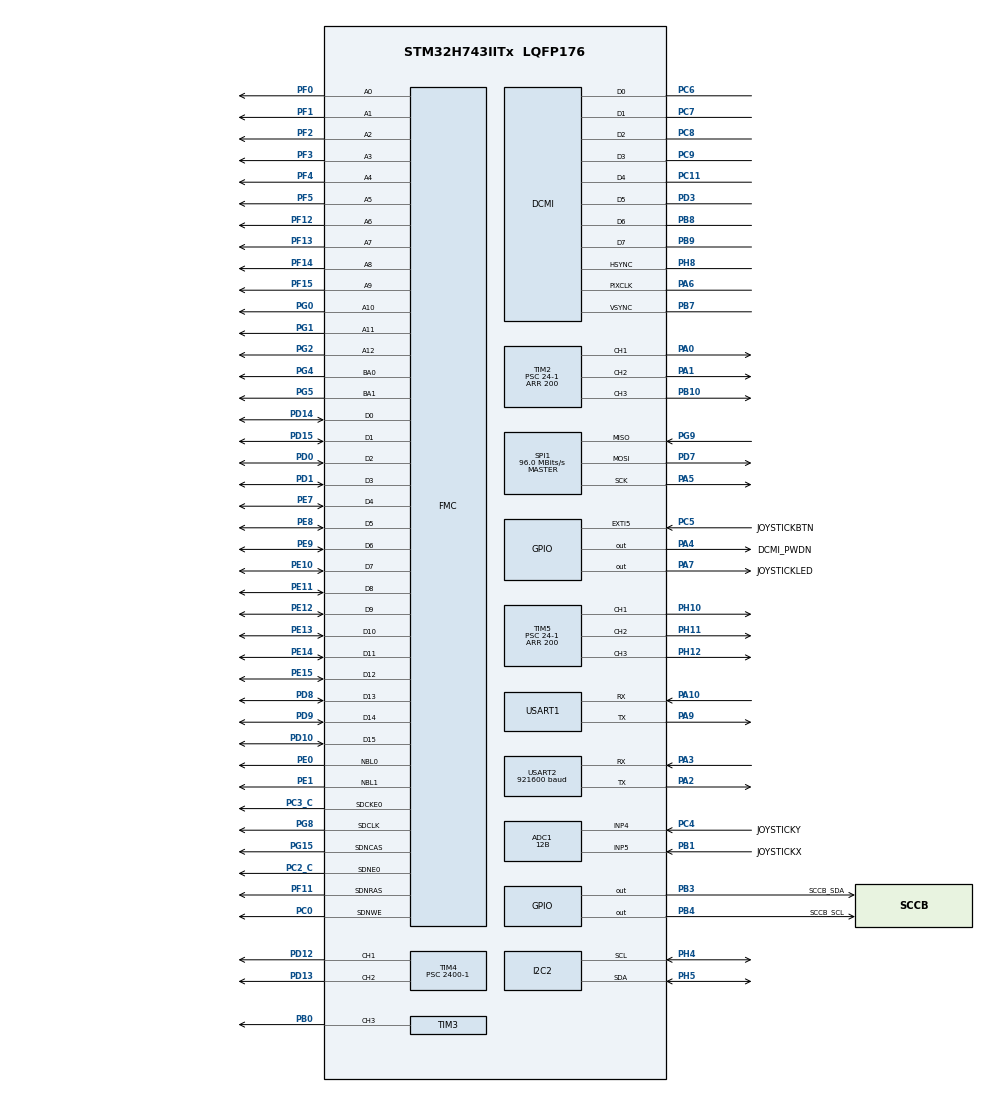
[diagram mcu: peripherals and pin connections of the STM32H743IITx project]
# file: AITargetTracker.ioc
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ADC1.Channel-1\#ChannelRegularConversion=ADC_CHANNEL_5
ADC1.Channel-3\#ChannelRegularConversion=ADC_CHANNEL_4
ADC1.ClockPrescaler=ADC_CLOCK_ASYNC_DIV2
ADC1.ContinuousConvMode=ENABLE
ADC1.ConversionDataManagement=ADC_CONVERSIONDATA_DMA_CIRCULAR
ADC1.EOCSelection=ADC_EOC_SEQ_CONV
ADC1.NbrOfConversion=2
ADC1.NbrOfConversionFlag=1
ADC1.OffsetNumber-1\#ChannelRegularConversion=ADC_OFFSET_NONE
ADC1.OffsetNumber-3\#ChannelRegularConversion=ADC_OFFSET_NONE
ADC1.OffsetSignedSaturation-1\#ChannelRegularConversion=DISABLE
ADC1.OffsetSignedSaturation-3\#ChannelRegularConversion=DISABLE
ADC1.Rank-1\#ChannelRegularConversion=1
ADC1.Rank-3\#ChannelRegularConversion=2
ADC1.Resolution=ADC_RESOLUTION_12B
ADC1.SamplingTime-1\#ChannelRegularConversion=ADC_SAMPLETIME_32CYCLES_5
ADC1.SamplingTime-3\#ChannelRegularConversion=ADC_SAMPLETIME_32CYCLES_5
ADC1.master=1
CORTEX_M7.AccessPermission_Spec=MPU_REGION_FULL_ACCESS
CORTEX_M7.Enable_S-Cortex_Memory_Protection_Unit_Region1_Settings_S=__NULL
CORTEX_M7.Enable_S-Cortex_Memory_Protection_Unit_Region6_Settings_S=__NULL
CORTEX_M7.default_mode_Activation=1
DCMI.PCKPolarity=DCMI_PCKPOLARITY_RISING
DMA2D.ColorMode=DMA2D_OUTPUT_RGB565
Dma.ADC1.2.Direction=DMA_PERIPH_TO_MEMORY
Dma.ADC1.2.EventEnable=DISABLE
Dma.ADC1.2.FIFOMode=DMA_FIFOMODE_DISABLE
Dma.ADC1.2.Instance=DMA1_Stream2
Dma.ADC1.2.MemDataAlignment=DMA_MDATAALIGN_HALFWORD
Dma.ADC1.2.MemInc=DMA_MINC_ENABLE
Dma.ADC1.2.Mode=DMA_CIRCULAR
Dma.ADC1.2.PeriphDataAlignment=DMA_PDATAALIGN_HALFWORD
Dma.ADC1.2.PeriphInc=DMA_PINC_DISABLE
Dma.ADC1.2.Polarity=HAL_DMAMUX_REQ_GEN_RISING
Dma.ADC1.2.Priority=DMA_PRIORITY_LOW
Dma.ADC1.2.RequestNumber=1
Dma.ADC1.2.SignalID=NONE
Dma.ADC1.2.SyncEnable=DISABLE
Dma.ADC1.2.SyncPolarity=HAL_DMAMUX_SYNC_NO_EVENT
Dma.ADC1.2.SyncRequestNumber=1
Dma.ADC1.2.SyncSignalID=NONE
Dma.DCMI.0.Direction=DMA_PERIPH_TO_MEMORY
Dma.DCMI.0.EventEnable=DISABLE
Dma.DCMI.0.FIFOMode=DMA_FIFOMODE_ENABLE
Dma.DCMI.0.FIFOThreshold=DMA_FIFO_THRESHOLD_FULL
Dma.DCMI.0.Instance=DMA1_Stream0
Dma.DCMI.0.MemBurst=DMA_MBURST_SINGLE
Dma.DCMI.0.MemDataAlignment=DMA_MDATAALIGN_WORD
Dma.DCMI.0.MemInc=DMA_MINC_ENABLE
Dma.DCMI.0.Mode=DMA_CIRCULAR
Dma.DCMI.0.PeriphBurst=DMA_PBURST_SINGLE
Dma.DCMI.0.PeriphDataAlignment=DMA_PDATAALIGN_WORD
Dma.DCMI.0.PeriphInc=DMA_PINC_DISABLE
Dma.DCMI.0.Polarity=HAL_DMAMUX_REQ_GEN_RISING
Dma.DCMI.0.Priority=DMA_PRIORITY_VERY_HIGH
Dma.DCMI.0.RequestNumber=1
Dma.DCMI.0.SignalID=NONE
Dma.DCMI.0.SyncEnable=DISABLE
Dma.DCMI.0.SyncPolarity=HAL_DMAMUX_SYNC_NO_EVENT
Dma.DCMI.0.SyncRequestNumber=1
Dma.DCMI.0.SyncSignalID=NONE
Dma.I2C2_RX.5.Direction=DMA_PERIPH_TO_MEMORY
Dma.I2C2_RX.5.EventEnable=DISABLE
Dma.I2C2_RX.5.FIFOMode=DMA_FIFOMODE_DISABLE
Dma.I2C2_RX.5.Instance=DMA2_Stream0
Dma.I2C2_RX.5.MemDataAlignment=DMA_MDATAALIGN_BYTE
Dma.I2C2_RX.5.MemInc=DMA_MINC_ENABLE
Dma.I2C2_RX.5.Mode=DMA_NORMAL
Dma.I2C2_RX.5.PeriphDataAlignment=DMA_PDATAALIGN_BYTE
Dma.I2C2_RX.5.PeriphInc=DMA_PINC_DISABLE
Dma.I2C2_RX.5.Polarity=HAL_DMAMUX_REQ_GEN_RISING
Dma.I2C2_RX.5.Priority=DMA_PRIORITY_LOW
Dma.I2C2_RX.5.RequestNumber=1
Dma.I2C2_RX.5.SignalID=NONE
Dma.I2C2_RX.5.SyncEnable=DISABLE
Dma.I2C2_RX.5.SyncPolarity=HAL_DMAMUX_SYNC_NO_EVENT
Dma.I2C2_RX.5.SyncRequestNumber=1
Dma.I2C2_RX.5.SyncSignalID=NONE
Dma.I2C2_TX.4.Direction=DMA_MEMORY_TO_PERIPH
Dma.I2C2_TX.4.EventEnable=DISABLE
Dma.I2C2_TX.4.FIFOMode=DMA_FIFOMODE_DISABLE
Dma.I2C2_TX.4.Instance=DMA2_Stream1
Dma.I2C2_TX.4.MemDataAlignment=DMA_MDATAALIGN_BYTE
Dma.I2C2_TX.4.MemInc=DMA_MINC_ENABLE
Dma.I2C2_TX.4.Mode=DMA_NORMAL
Dma.I2C2_TX.4.PeriphDataAlignment=DMA_PDATAALIGN_BYTE
Dma.I2C2_TX.4.PeriphInc=DMA_PINC_DISABLE
Dma.I2C2_TX.4.Polarity=HAL_DMAMUX_REQ_GEN_RISING
Dma.I2C2_TX.4.Priority=DMA_PRIORITY_LOW
Dma.I2C2_TX.4.RequestNumber=1
Dma.I2C2_TX.4.SignalID=NONE
Dma.I2C2_TX.4.SyncEnable=DISABLE
Dma.I2C2_TX.4.SyncPolarity=HAL_DMAMUX_SYNC_NO_EVENT
Dma.I2C2_TX.4.SyncRequestNumber=1
Dma.I2C2_TX.4.SyncSignalID=NONE
Dma.Request0=DCMI
Dma.Request1=SPI1_TX
Dma.Request2=ADC1
Dma.Request3=USART2_TX
Dma.Request4=I2C2_TX
Dma.Request5=I2C2_RX
Dma.Request6=USART1_RX
Dma.Request7=USART1_TX
Dma.SPI1_TX.1.Direction=DMA_MEMORY_TO_PERIPH
Dma.SPI1_TX.1.EventEnable=DISABLE
Dma.SPI1_TX.1.FIFOMode=DMA_FIFOMODE_DISABLE
Dma.SPI1_TX.1.Instance=DMA1_Stream1
Dma.SPI1_TX.1.MemDataAlignment=DMA_MDATAALIGN_HALFWORD
Dma.SPI1_TX.1.MemInc=DMA_MINC_ENABLE
Dma.SPI1_TX.1.Mode=DMA_NORMAL
Dma.SPI1_TX.1.PeriphDataAlignment=DMA_PDATAALIGN_HALFWORD
Dma.SPI1_TX.1.PeriphInc=DMA_PINC_DISABLE
Dma.SPI1_TX.1.Polarity=HAL_DMAMUX_REQ_GEN_RISING
Dma.SPI1_TX.1.Priority=DMA_PRIORITY_LOW
Dma.SPI1_TX.1.RequestNumber=1
Dma.SPI1_TX.1.SignalID=NONE
Dma.SPI1_TX.1.SyncEnable=DISABLE
Dma.SPI1_TX.1.SyncPolarity=HAL_DMAMUX_SYNC_NO_EVENT
Dma.SPI1_TX.1.SyncRequestNumber=1
Dma.SPI1_TX.1.SyncSignalID=NONE
Dma.USART1_RX.6.Direction=DMA_PERIPH_TO_MEMORY
Dma.USART1_RX.6.EventEnable=DISABLE
Dma.USART1_RX.6.FIFOMode=DMA_FIFOMODE_DISABLE
Dma.USART1_RX.6.Instance=DMA1_Stream4
Dma.USART1_RX.6.MemDataAlignment=DMA_MDATAALIGN_BYTE
Dma.USART1_RX.6.MemInc=DMA_MINC_ENABLE
Dma.USART1_RX.6.Mode=DMA_NORMAL
Dma.USART1_RX.6.PeriphDataAlignment=DMA_PDATAALIGN_BYTE
Dma.USART1_RX.6.PeriphInc=DMA_PINC_DISABLE
Dma.USART1_RX.6.Polarity=HAL_DMAMUX_REQ_GEN_RISING
Dma.USART1_RX.6.Priority=DMA_PRIORITY_LOW
Dma.USART1_RX.6.RequestNumber=1
Dma.USART1_RX.6.SignalID=NONE
Dma.USART1_RX.6.SyncEnable=DISABLE
Dma.USART1_RX.6.SyncPolarity=HAL_DMAMUX_SYNC_NO_EVENT
Dma.USART1_RX.6.SyncRequestNumber=1
Dma.USART1_RX.6.SyncSignalID=NONE
Dma.USART1_TX.7.Direction=DMA_MEMORY_TO_PERIPH
Dma.USART1_TX.7.EventEnable=DISABLE
Dma.USART1_TX.7.FIFOMode=DMA_FIFOMODE_DISABLE
Dma.USART1_TX.7.Instance=DMA1_Stream5
Dma.USART1_TX.7.MemDataAlignment=DMA_MDATAALIGN_BYTE
Dma.USART1_TX.7.MemInc=DMA_MINC_ENABLE
Dma.USART1_TX.7.Mode=DMA_NORMAL
Dma.USART1_TX.7.PeriphDataAlignment=DMA_PDATAALIGN_BYTE
Dma.USART1_TX.7.PeriphInc=DMA_PINC_DISABLE
Dma.USART1_TX.7.Polarity=HAL_DMAMUX_REQ_GEN_RISING
Dma.USART1_TX.7.Priority=DMA_PRIORITY_LOW
Dma.USART1_TX.7.RequestNumber=1
Dma.USART1_TX.7.SignalID=NONE
Dma.USART1_TX.7.SyncEnable=DISABLE
Dma.USART1_TX.7.SyncPolarity=HAL_DMAMUX_SYNC_NO_EVENT
Dma.USART1_TX.7.SyncRequestNumber=1
Dma.USART1_TX.7.SyncSignalID=NONE
Dma.USART2_TX.3.Direction=DMA_MEMORY_TO_PERIPH
Dma.USART2_TX.3.EventEnable=DISABLE
Dma.USART2_TX.3.FIFOMode=DMA_FIFOMODE_DISABLE
Dma.USART2_TX.3.Instance=DMA1_Stream3
Dma.USART2_TX.3.MemDataAlignment=DMA_MDATAALIGN_BYTE
Dma.USART2_TX.3.MemInc=DMA_MINC_ENABLE
Dma.USART2_TX.3.Mode=DMA_NORMAL
Dma.USART2_TX.3.PeriphDataAlignment=DMA_PDATAALIGN_BYTE
Dma.USART2_TX.3.PeriphInc=DMA_PINC_DISABLE
Dma.USART2_TX.3.Polarity=HAL_DMAMUX_REQ_GEN_RISING
Dma.USART2_TX.3.Priority=DMA_PRIORITY_LOW
Dma.USART2_TX.3.RequestNumber=1
Dma.USART2_TX.3.SignalID=NONE
Dma.USART2_TX.3.SyncEnable=DISABLE
Dma.USART2_TX.3.SyncPolarity=HAL_DMAMUX_SYNC_NO_EVENT
Dma.USART2_TX.3.SyncRequestNumber=1
Dma.USART2_TX.3.SyncSignalID=NONE
FMC.CASLatency1=FMC_SDRAM_CAS_LATENCY_3
FMC.ColumnBitsNumber1=FMC_SDRAM_COLUMN_BITS_NUM_9
FMC.ExitSelfRefreshDelay1=9
FMC.LoadToActiveDelay1=2
FMC.RCDDelay1=2
FMC.RPDelay1=2
FMC.RPDelay2=2
FMC.ReadBurst1=FMC_SDRAM_RBURST_ENABLE
FMC.ReadBurst2=FMC_SDRAM_RBURST_ENABLE
FMC.ReadPipeDelay1=FMC_SDRAM_RPIPE_DELAY_1
FMC.ReadPipeDelay2=FMC_SDRAM_RPIPE_DELAY_1
FMC.RowCycleDelay1=8
FMC.RowCycleDelay2=8
FMC.SDClockPeriod1=FMC_SDRAM_CLOCK_PERIOD_2
FMC.SDClockPeriod2=FMC_SDRAM_CLOCK_PERIOD_2
FMC.SelfRefreshTime1=6
FMC.WriteRecoveryTime1=4
FREERTOS.Tasks01=defaultTask,0,128,StartDefaultTask,Default,NULL,Dynamic,NULL,NULL
FREERTOS.configUSE_TIMERS=1
I2C2.I2C_Fall_Time=5
I2C2.I2C_Rise_Time=5
I2C2.Timing=0x60404364
JPEG.JPEG_RGB_FORMAT=JPEG_RGB565
Mcu.Family=STM32H7
Mcu.Name=STM32H743IITx
Mcu.Package=LQFP176
Mdma.MDMA_Channel0.JPEG_INFIFO_NF.0.BlockCount=0
Mdma.MDMA_Channel0.JPEG_INFIFO_NF.0.BlockDataLength=0
Mdma.MDMA_Channel0.JPEG_INFIFO_NF.0.BufferTransferLength=4
Mdma.MDMA_Channel0.JPEG_INFIFO_NF.0.CircularMode=MDMA_LINEAR_LIST
Mdma.MDMA_Channel0.JPEG_INFIFO_NF.0.DataAlignment=MDMA_DATAALIGN_PACKENABLE
Mdma.MDMA_Channel0.JPEG_INFIFO_NF.0.DestBlockAddressOffset=0
Mdma.MDMA_Channel0.JPEG_INFIFO_NF.0.DestBurst=MDMA_DEST_BURST_SINGLE
Mdma.MDMA_Channel0.JPEG_INFIFO_NF.0.DestDataSize=MDMA_DEST_DATASIZE_WORD
Mdma.MDMA_Channel0.JPEG_INFIFO_NF.0.DestinationInc=MDMA_DEST_INC_DISABLE
Mdma.MDMA_Channel0.JPEG_INFIFO_NF.0.DstAddress=0
Mdma.MDMA_Channel0.JPEG_INFIFO_NF.0.Endianness=MDMA_LITTLE_ENDIANNESS_PRESERVE
Mdma.MDMA_Channel0.JPEG_INFIFO_NF.0.Instance=MDMA_Channel0
Mdma.MDMA_Channel0.JPEG_INFIFO_NF.0.MaskAddress=0 
Mdma.MDMA_Channel0.JPEG_INFIFO_NF.0.MaskData=0
Mdma.MDMA_Channel0.JPEG_INFIFO_NF.0.Priority=MDMA_PRIORITY_HIGH
Mdma.MDMA_Channel0.JPEG_INFIFO_NF.0.Rank=First
Mdma.MDMA_Channel0.JPEG_INFIFO_NF.0.SourceBlockAddressOffset=0
Mdma.MDMA_Channel0.JPEG_INFIFO_NF.0.SourceBurst=MDMA_SOURCE_BURST_SINGLE
Mdma.MDMA_Channel0.JPEG_INFIFO_NF.0.SourceDataSize=MDMA_SRC_DATASIZE_BYTE
Mdma.MDMA_Channel0.JPEG_INFIFO_NF.0.SourceInc=MDMA_SRC_INC_BYTE
Mdma.MDMA_Channel0.JPEG_INFIFO_NF.0.SrcAddress=0
Mdma.MDMA_Channel0.JPEG_INFIFO_NF.0.TransferTriggerMode=MDMA_BUFFER_TRANSFER
Mdma.MDMA_Channel0.Request0=JPEG_INFIFO_NF
Mdma.MDMA_Channel0.RequestsNb=1
Mdma.MDMA_Channel1.JPEG_OUTFIFO_NE.0.BlockCount=0
Mdma.MDMA_Channel1.JPEG_OUTFIFO_NE.0.BlockDataLength=0
Mdma.MDMA_Channel1.JPEG_OUTFIFO_NE.0.BufferTransferLength=4
Mdma.MDMA_Channel1.JPEG_OUTFIFO_NE.0.CircularMode=MDMA_LINEAR_LIST
Mdma.MDMA_Channel1.JPEG_OUTFIFO_NE.0.DataAlignment=MDMA_DATAALIGN_PACKENABLE
Mdma.MDMA_Channel1.JPEG_OUTFIFO_NE.0.DestBlockAddressOffset=0
Mdma.MDMA_Channel1.JPEG_OUTFIFO_NE.0.DestBurst=MDMA_DEST_BURST_SINGLE
Mdma.MDMA_Channel1.JPEG_OUTFIFO_NE.0.DestDataSize=MDMA_DEST_DATASIZE_BYTE
Mdma.MDMA_Channel1.JPEG_OUTFIFO_NE.0.DestinationInc=MDMA_DEST_INC_BYTE
Mdma.MDMA_Channel1.JPEG_OUTFIFO_NE.0.DstAddress=0
Mdma.MDMA_Channel1.JPEG_OUTFIFO_NE.0.Endianness=MDMA_LITTLE_ENDIANNESS_PRESERVE
Mdma.MDMA_Channel1.JPEG_OUTFIFO_NE.0.Instance=MDMA_Channel1
Mdma.MDMA_Channel1.JPEG_OUTFIFO_NE.0.MaskAddress=0
Mdma.MDMA_Channel1.JPEG_OUTFIFO_NE.0.MaskData=0
Mdma.MDMA_Channel1.JPEG_OUTFIFO_NE.0.Priority=MDMA_PRIORITY_HIGH
Mdma.MDMA_Channel1.JPEG_OUTFIFO_NE.0.Rank=First
Mdma.MDMA_Channel1.JPEG_OUTFIFO_NE.0.SourceBlockAddressOffset=0
Mdma.MDMA_Channel1.JPEG_OUTFIFO_NE.0.SourceBurst=MDMA_SOURCE_BURST_SINGLE
Mdma.MDMA_Channel1.JPEG_OUTFIFO_NE.0.SourceDataSize=MDMA_SRC_DATASIZE_WORD
Mdma.MDMA_Channel1.JPEG_OUTFIFO_NE.0.SourceInc=MDMA_SRC_INC_DISABLE
Mdma.MDMA_Channel1.JPEG_OUTFIFO_NE.0.SrcAddress=0
Mdma.MDMA_Channel1.JPEG_OUTFIFO_NE.0.TransferTriggerMode=MDMA_BUFFER_TRANSFER
Mdma.MDMA_Channel1.Request0=JPEG_OUTFIFO_NE
Mdma.MDMA_Channel1.RequestsNb=1
Mdma.RequestSet0=MDMA_Channel0
Mdma.RequestSet1=MDMA_Channel1
Mdma.RequestSetsNb=2
NVIC.DCMI_IRQn=true\:5\:0\:false\:false\:true\:true\:true\:true\:true
NVIC.DMA1_Stream0_IRQn=true\:5\:0\:false\:false\:true\:true\:false\:true\:true
NVIC.DMA1_Stream1_IRQn=true\:5\:0\:false\:false\:true\:true\:false\:true\:true
NVIC.DMA1_Stream3_IRQn=true\:5\:0\:false\:false\:true\:true\:true\:true\:true
NVIC.DMA1_Stream4_IRQn=true\:5\:0\:false\:false\:true\:true\:true\:true\:true
NVIC.DMA1_Stream5_IRQn=true\:5\:0\:false\:false\:true\:true\:true\:true\:true
NVIC.DMA2_Stream0_IRQn=true\:5\:0\:false\:false\:true\:false\:true\:true\:true
NVIC.EXTI9_5_IRQn=true\:5\:0\:false\:false\:true\:true\:true\:true\:true
NVIC.I2C2_ER_IRQn=true\:5\:0\:false\:false\:true\:true\:true\:true\:true
NVIC.I2C2_EV_IRQn=true\:5\:0\:false\:false\:true\:true\:true\:true\:true
NVIC.MDMA_IRQn=true\:5\:0\:false\:false\:true\:true\:true\:true\:true
NVIC.PriorityGroup=NVIC_PRIORITYGROUP_4
NVIC.SPI1_IRQn=true\:5\:0\:false\:false\:true\:true\:false\:true\:true
NVIC.TIM1_UP_IRQn=true\:15\:0\:false\:false\:true\:false\:false\:true\:true
NVIC.TIM6_DAC_IRQn=true\:5\:0\:false\:false\:true\:true\:true\:true\:true
NVIC.TIM7_IRQn=true\:5\:0\:false\:false\:true\:true\:true\:true\:true
NVIC.TimeBase=TIM1_UP_IRQn
NVIC.TimeBaseIP=TIM1
NVIC.USART1_IRQn=true\:5\:0\:false\:false\:true\:true\:true\:true\:true
NVIC.USART2_IRQn=true\:5\:0\:false\:false\:true\:true\:true\:true\:true
PA0.Signal=S_TIM2_CH1_ETR
PA1.Signal=S_TIM2_CH2
PA10.Mode=Asynchronous
PA10.PinAttribute=Free
PA10.Signal=USART1_RX
PA13\ (JTMS/SWDIO).Mode=Serial_Wire
PA13\ (JTMS/SWDIO).PinAttribute=Free
PA13\ (JTMS/SWDIO).Signal=DEBUG_JTMS-SWDIO
PA14\ (JTCK/SWCLK).Mode=Serial_Wire
PA14\ (JTCK/SWCLK).PinAttribute=Free
PA14\ (JTCK/SWCLK).Signal=DEBUG_JTCK-SWCLK
PA2.Mode=Asynchronous
PA2.Signal=USART2_TX
PA3.Mode=Asynchronous
PA3.Signal=USART2_RX
PA4.GPIO_Label=DCMI_PWDN
PA4.PinState=GPIO_PIN_SET
PA4.Signal=GPIO_Output
PA5.Mode=Full_Duplex_Master
PA5.Signal=SPI1_SCK
PA6.GPIO_Speed=GPIO_SPEED_FREQ_VERY_HIGH
PA6.Mode=Slave_8_bits_External_Synchro
PA6.Signal=DCMI_PIXCLK
PA7.GPIO_Label=JOYSTICKLED
PA7.Signal=GPIO_Output
PA9.Mode=Asynchronous
PA9.PinAttribute=Free
PA9.Signal=USART1_TX
PB0.Signal=S_TIM3_CH3
PB1.GPIO_Label=JOYSTICKX
PB1.Signal=ADCx_INP5
PB10.Signal=S_TIM2_CH3
PB3\ (JTDO/TRACESWO).GPIO_Label=SCCB_SDA
PB3\ (JTDO/TRACESWO).GPIO_ModeDefaultOutputPP=GPIO_MODE_OUTPUT_OD
PB3\ (JTDO/TRACESWO).GPIO_PuPd=GPIO_NOPULL
PB3\ (JTDO/TRACESWO).GPIO_Speed=GPIO_SPEED_FREQ_LOW
PB3\ (JTDO/TRACESWO).PinAttribute=Free
PB3\ (JTDO/TRACESWO).PinState=GPIO_PIN_RESET
PB3\ (JTDO/TRACESWO).Signal=GPIO_Output
PB4\ (NJTRST).GPIO_Label=SCCB_SCL
PB4\ (NJTRST).GPIO_ModeDefaultOutputPP=GPIO_MODE_OUTPUT_OD
PB4\ (NJTRST).GPIO_PuPd=GPIO_NOPULL
PB4\ (NJTRST).PinAttribute=Free
PB4\ (NJTRST).PinState=GPIO_PIN_RESET
PB4\ (NJTRST).Signal=GPIO_Output
PB7.GPIO_Speed=GPIO_SPEED_FREQ_VERY_HIGH
PB7.Mode=Slave_8_bits_External_Synchro
PB7.PinAttribute=Free
PB7.Signal=DCMI_VSYNC
PB8.GPIO_FM8=__NULL
PB8.GPIO_Speed=GPIO_SPEED_FREQ_VERY_HIGH
PB8.Mode=Slave_8_bits_External_Synchro
PB8.Signal=DCMI_D6
PB9.GPIO_Speed=GPIO_SPEED_FREQ_VERY_HIGH
PB9.Mode=Slave_8_bits_External_Synchro
PB9.Signal=DCMI_D7
PC0.Signal=FMC_SDNWE
PC11.GPIO_Speed=GPIO_SPEED_FREQ_VERY_HIGH
PC11.Mode=Slave_8_bits_External_Synchro
PC11.PinAttribute=Free
PC11.Signal=DCMI_D4
PC14-OSC32_IN\ (OSC32_IN).Mode=LSE-External-Oscillator
PC14-OSC32_IN\ (OSC32_IN).Signal=RCC_OSC32_IN
PC15-OSC32_OUT\ (OSC32_OUT).Mode=LSE-External-Oscillator
PC15-OSC32_OUT\ (OSC32_OUT).Signal=RCC_OSC32_OUT
PC2_C.Mode=SdramChipSelect1_1
PC2_C.Signal=FMC_SDNE0
PC3_C.Mode=SdramChipSelect1_1
PC3_C.Signal=FMC_SDCKE0
PC4.GPIO_Label=JOYSTICKY
PC4.Signal=ADCx_INP4
PC5.GPIO_Label=JOYSTICKBTN
PC5.GPIO_ModeDefaultEXTI=GPIO_MODE_IT_FALLING
PC5.GPIO_PuPd=GPIO_PULLUP
PC5.Signal=GPXTI5
PC6.GPIO_Speed=GPIO_SPEED_FREQ_VERY_HIGH
PC6.Mode=Slave_8_bits_External_Synchro
PC6.Signal=DCMI_D0
PC7.GPIO_Speed=GPIO_SPEED_FREQ_VERY_HIGH
PC7.Mode=Slave_8_bits_External_Synchro
PC7.Signal=DCMI_D1
PC8.GPIO_Speed=GPIO_SPEED_FREQ_VERY_HIGH
PC8.Mode=Slave_8_bits_External_Synchro
PC8.Signal=DCMI_D2
PC9.GPIO_Speed=GPIO_SPEED_FREQ_VERY_HIGH
PC9.Mode=Slave_8_bits_External_Synchro
PC9.Signal=DCMI_D3
PD0.PinAttribute=Free
PD0.Signal=FMC_D2_DA2
PD1.PinAttribute=Free
PD1.Signal=FMC_D3_DA3
PD10.Signal=FMC_D15_DA15
PD12.Signal=S_TIM4_CH1
PD13.Signal=S_TIM4_CH2
PD14.Signal=FMC_D0_DA0
PD15.Signal=FMC_D1_DA1
PD3.GPIO_Speed=GPIO_SPEED_FREQ_VERY_HIGH
PD3.Mode=Slave_8_bits_External_Synchro
PD3.PinAttribute=Free
PD3.Signal=DCMI_D5
PD7.Mode=Full_Duplex_Master
PD7.PinAttribute=Free
PD7.Signal=SPI1_MOSI
PD8.Signal=FMC_D13_DA13
PD9.Signal=FMC_D14_DA14
PE0.Signal=FMC_NBL0
PE1.Signal=FMC_NBL1
PE10.Signal=FMC_D7_DA7
PE11.Signal=FMC_D8_DA8
PE12.Signal=FMC_D9_DA9
PE13.Signal=FMC_D10_DA10
PE14.Signal=FMC_D11_DA11
PE15.Signal=FMC_D12_DA12
PE7.Signal=FMC_D4_DA4
PE8.Signal=FMC_D5_DA5
PE9.Signal=FMC_D6_DA6
PF0.Signal=FMC_A0
PF1.Signal=FMC_A1
PF11.Signal=FMC_SDNRAS
PF12.Signal=FMC_A6
PF13.Signal=FMC_A7
PF14.Signal=FMC_A8
PF15.Signal=FMC_A9
PF2.Signal=FMC_A2
PF3.Signal=FMC_A3
PF4.Signal=FMC_A4
PF5.Signal=FMC_A5
PG0.Signal=FMC_A10
PG1.Signal=FMC_A11
PG15.PinAttribute=Free
PG15.Signal=FMC_SDNCAS
PG2.Signal=FMC_A12
PG4.Signal=FMC_A14_BA0
PG5.Signal=FMC_A15_BA1
PG8.Signal=FMC_SDCLK
PG9.Mode=Full_Duplex_Master
PG9.PinAttribute=Free
PG9.Signal=SPI1_MISO
PH0-OSC_IN\ (PH0).Mode=HSE-External-Oscillator
PH0-OSC_IN\ (PH0).Signal=RCC_OSC_IN
PH1-OSC_OUT\ (PH1).Mode=HSE-External-Oscillator
PH1-OSC_OUT\ (PH1).Signal=RCC_OSC_OUT
PH10.Signal=S_TIM5_CH1
PH11.Signal=S_TIM5_CH2
PH12.Signal=S_TIM5_CH3
PH4.Mode=I2C
PH4.Signal=I2C2_SCL
PH5.Mode=I2C
PH5.Signal=I2C2_SDA
PH8.GPIO_Speed=GPIO_SPEED_FREQ_VERY_HIGH
PH8.Mode=Slave_8_bits_External_Synchro
PH8.Signal=DCMI_HSYNC
ProjectManager.HeapSize=0x200
ProjectManager.StackSize=0x400
ProjectManager.TargetToolchain=MDK-ARM V5.32
RCC.ADCCLockSelection=RCC_ADCCLKSOURCE_PLL3
RCC.ADCFreq_Value=80000000
RCC.APB1Freq_Value=120000000
RCC.APB2Freq_Value=120000000
RCC.APB3Freq_Value=120000000
RCC.APB4Freq_Value=120000000
RCC.CortexFreq_Value=480000000
RCC.D1PPRE=RCC_APB3_DIV2
RCC.D2PPRE1=RCC_APB1_DIV2
RCC.D2PPRE2=RCC_APB2_DIV2
RCC.D3PPRE=RCC_APB4_DIV2
RCC.DIVM1=4
RCC.DIVM2=4
RCC.DIVM3=20
RCC.DIVN1=60
RCC.DIVN2=15
RCC.DIVN3=75
RCC.DIVQ1=5
RCC.DIVQ2=10
RCC.DIVQ3=1
RCC.DIVR2=1
RCC.DIVR3=3
RCC.FMCCLockSelection=RCC_FMCCLKSOURCE_PLL2
RCC.HCLKFreq_Value=240000000
RCC.HPRE=RCC_HCLK_DIV2
RCC.PLL2FRACN=0
RCC.PLL3FRACN=0
RCC.PLLFRACN=0
RCC.SYSCLKFreq_VALUE=480000000
RCC.SYSCLKSource=RCC_SYSCLKSOURCE_PLLCLK
RCC.USBFreq_Value=192000000
SH.ADCx_INP4.0=ADC1_INP4,IN4-Single-Ended
SH.ADCx_INP5.0=ADC1_INP5,IN5-Single-Ended
SH.FMC_A0.0=FMC_A0,13b-sda1
SH.FMC_A1.0=FMC_A1,13b-sda1
SH.FMC_A10.0=FMC_A10,13b-sda1
SH.FMC_A11.0=FMC_A11,13b-sda1
SH.FMC_A12.0=FMC_A12,13b-sda1
SH.FMC_A14_BA0.0=FMC_BA0,FourSdramBanks1
SH.FMC_A15_BA1.0=FMC_BA1,FourSdramBanks1
SH.FMC_A2.0=FMC_A2,13b-sda1
SH.FMC_A3.0=FMC_A3,13b-sda1
SH.FMC_A4.0=FMC_A4,13b-sda1
SH.FMC_A5.0=FMC_A5,13b-sda1
SH.FMC_A6.0=FMC_A6,13b-sda1
SH.FMC_A7.0=FMC_A7,13b-sda1
SH.FMC_A8.0=FMC_A8,13b-sda1
SH.FMC_A9.0=FMC_A9,13b-sda1
SH.FMC_D0_DA0.0=FMC_D0,sd-16b-d1
SH.FMC_D10_DA10.0=FMC_D10,sd-16b-d1
SH.FMC_D11_DA11.0=FMC_D11,sd-16b-d1
SH.FMC_D12_DA12.0=FMC_D12,sd-16b-d1
SH.FMC_D13_DA13.0=FMC_D13,sd-16b-d1
SH.FMC_D14_DA14.0=FMC_D14,sd-16b-d1
SH.FMC_D15_DA15.0=FMC_D15,sd-16b-d1
SH.FMC_D1_DA1.0=FMC_D1,sd-16b-d1
SH.FMC_D2_DA2.0=FMC_D2,sd-16b-d1
SH.FMC_D3_DA3.0=FMC_D3,sd-16b-d1
SH.FMC_D4_DA4.0=FMC_D4,sd-16b-d1
SH.FMC_D5_DA5.0=FMC_D5,sd-16b-d1
SH.FMC_D6_DA6.0=FMC_D6,sd-16b-d1
SH.FMC_D7_DA7.0=FMC_D7,sd-16b-d1
SH.FMC_D8_DA8.0=FMC_D8,sd-16b-d1
SH.FMC_D9_DA9.0=FMC_D9,sd-16b-d1
SH.FMC_NBL0.0=FMC_NBL0,Sd2ByteEnable1
SH.FMC_NBL1.0=FMC_NBL1,Sd2ByteEnable1
SH.FMC_SDCLK.0=FMC_SDCLK,13b-sda1
SH.FMC_SDNCAS.0=FMC_SDNCAS,13b-sda1
SH.FMC_SDNRAS.0=FMC_SDNRAS,13b-sda1
SH.FMC_SDNWE.0=FMC_SDNWE,13b-sda1
SH.S_TIM2_CH1_ETR.0=TIM2_CH1,PWM Generation1 CH1
SH.S_TIM2_CH2.0=TIM2_CH2,PWM Generation2 CH2
SH.S_TIM2_CH3.0=TIM2_CH3,PWM Generation3 CH3
SH.S_TIM3_CH3.0=TIM3_CH3,PWM Generation3 CH3
SH.S_TIM4_CH1.0=TIM4_CH1,PWM Generation1 CH1
SH.S_TIM4_CH2.0=TIM4_CH2,PWM Generation2 CH2
SH.S_TIM5_CH1.0=TIM5_CH1,PWM Generation1 CH1
SH.S_TIM5_CH2.0=TIM5_CH2,PWM Generation2 CH2
SH.S_TIM5_CH3.0=TIM5_CH3,PWM Generation3 CH3
SPI1.CalculateBaudRate=96.0 MBits/s
SPI1.Direction=SPI_DIRECTION_2LINES
SPI1.Mode=SPI_MODE_MASTER
SPI1.VirtualType=VM_MASTER
TIM2.AutoReloadPreload=TIM_AUTORELOAD_PRELOAD_ENABLE
TIM2.Channel-PWM\ Generation1\ CH1=TIM_CHANNEL_1
TIM2.Channel-PWM\ Generation2\ CH2=TIM_CHANNEL_2
TIM2.Channel-PWM\ Generation3\ CH3=TIM_CHANNEL_3
TIM2.CounterMode=TIM_COUNTERMODE_CENTERALIGNED2
TIM2.Period=200
TIM2.Prescaler=24-1
TIM3.AutoReloadPreload=TIM_AUTORELOAD_PRELOAD_ENABLE
TIM3.Channel-PWM\ Generation3\ CH3=TIM_CHANNEL_3
TIM3.Period=1000
TIM4.AutoReloadPreload=TIM_AUTORELOAD_PRELOAD_ENABLE
TIM4.Channel-PWM\ Generation1\ CH1=TIM_CHANNEL_1
TIM4.Channel-PWM\ Generation2\ CH2=TIM_CHANNEL_2
TIM4.Period=2000-1
TIM4.Prescaler=2400-1
TIM5.AutoReloadPreload=TIM_AUTORELOAD_PRELOAD_ENABLE
TIM5.Channel-PWM\ Generation1\ CH1=TIM_CHANNEL_1
TIM5.Channel-PWM\ Generation2\ CH2=TIM_CHANNEL_2
TIM5.Channel-PWM\ Generation3\ CH3=TIM_CHANNEL_3
TIM5.CounterMode=TIM_COUNTERMODE_CENTERALIGNED1
TIM5.Period=200
TIM5.Prescaler=24-1
TIM6.AutoReloadPreload=TIM_AUTORELOAD_PRELOAD_ENABLE
TIM6.Period=8000
TIM6.Prescaler=240
TIM7.AutoReloadPreload=TIM_AUTORELOAD_PRELOAD_ENABLE
TIM7.Period=200
TIM7.Prescaler=240
USART1.VirtualMode-Asynchronous=VM_ASYNC
USART2.BaudRate=921600
USART2.Mode=MODE_TX_RX
USART2.VirtualMode-Asynchronous=VM_ASYNC
VP_DMA2D_VS_DMA2D.Mode=DMA2D_Activate
VP_FREERTOS_VS_CMSIS_V1.Mode=CMSIS_V1
VP_JPEG_VS_JPEG.Mode=JPEG_Activate
VP_MEMORYMAP_VS_MEMORYMAP.Mode=CurAppReg
VP_SYS_VS_tim1.Mode=TIM1
VP_TIM2_VS_ClockSourceINT.Mode=Internal
VP_TIM4_VS_ClockSourceINT.Mode=Internal
VP_TIM5_VS_ClockSourceINT.Mode=Internal
VP_TIM6_VS_ClockSourceINT.Mode=Enable_Timer
VP_TIM7_VS_ClockSourceINT.Mode=Enable_Timer
board=custom

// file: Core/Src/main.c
/* USER CODE BEGIN Header */
/**
  ******************************************************************************
  * @file           : main.c
  * @brief          : Main program body
  ******************************************************************************
  * @attention
  *
  * Copyright (c) 2025 STMicroelectronics.
  * All rights reserved.
  *
  * This software is licensed under terms that can be found in the LICENSE file
  * in the root directory of this software component.
  * If no LICENSE file comes with this software, it is provided AS-IS.
  *
  ******************************************************************************
  */
/* USER CODE END Header */
#include "main.h"
#include "cmsis_os.h"
#include "adc.h"
#include "dcmi.h"
#include "dma.h"
#include "dma2d.h"
#include "i2c.h"
#include "jpeg.h"
#include "mdma.h"
#include "spi.h"
#include "tim.h"
#include "usart.h"
#include "gpio.h"
#include "fmc.h"

/* USER CODE BEGIN Includes */

#include "SDRAM.h"
#include "dcmi_ov5640.h"

/* USER CODE END Includes */

void SystemClock_Config(void);
static void MPU_Config(void);
void MX_FREERTOS_Init(void);

int main(void)
{

  /* MPU Configuration--------------------------------------------------------*/
  MPU_Config();

  /* MCU Configuration--------------------------------------------------------*/

  /* Reset of all peripherals, Initializes the Flash interface and the Systick. */
  HAL_Init();

  /* Configure the system clock */
  SystemClock_Config();

  /* Initialize all configured peripherals */
  MX_GPIO_Init();
  MX_DMA_Init();
  MX_MDMA_Init();
  MX_FMC_Init();
  MX_USART1_UART_Init();
  MX_DCMI_Init();
  MX_DMA2D_Init();
  MX_JPEG_Init();
  MX_SPI1_Init();
  MX_TIM4_Init();
  MX_ADC1_Init();
  MX_USART2_UART_Init();
  MX_TIM5_Init();
  MX_TIM2_Init();
  MX_TIM3_Init();
  MX_TIM6_Init();
  MX_TIM7_Init();
  MX_I2C2_Init();
  /* USER CODE BEGIN 2 */

	SDRAM_Init();
	//DCMI_OV5640_Init();
	HAL_Delay(10);

  /* USER CODE END 2 */

  /* Call init function for freertos objects (in cmsis_os2.c) */
  MX_FREERTOS_Init();

  /* Start scheduler */
  osKernelStart();

  /* We should never get here as control is now taken by the scheduler */

  /* Infinite loop */
  while (1)
  {

  }
}

void SystemClock_Config(void)
{
  RCC_OscInitTypeDef RCC_OscInitStruct = {0};
  RCC_ClkInitTypeDef RCC_ClkInitStruct = {0};

  /** Supply configuration update enable
  */
  HAL_PWREx_ConfigSupply(PWR_LDO_SUPPLY);

  /** Configure the main internal regulator output voltage
  */
  __HAL_PWR_VOLTAGESCALING_CONFIG(PWR_REGULATOR_VOLTAGE_SCALE0);

  while(!__HAL_PWR_GET_FLAG(PWR_FLAG_VOSRDY)) {}

  /** Initializes the RCC Oscillators according to the specified parameters
  * in the RCC_OscInitTypeDef structure.
  */
  RCC_OscInitStruct.OscillatorType = RCC_OSCILLATORTYPE_HSI;
  RCC_OscInitStruct.HSIState = RCC_HSI_DIV1;
  RCC_OscInitStruct.HSICalibrationValue = RCC_HSICALIBRATION_DEFAULT;
  RCC_OscInitStruct.PLL.PLLState = RCC_PLL_ON;
  RCC_OscInitStruct.PLL.PLLSource = RCC_PLLSOURCE_HSI;
  RCC_OscInitStruct.PLL.PLLM = 4;
  RCC_OscInitStruct.PLL.PLLN = 60;
  RCC_OscInitStruct.PLL.PLLP = 2;
  RCC_OscInitStruct.PLL.PLLQ = 5;
  RCC_OscInitStruct.PLL.PLLR = 2;
  RCC_OscInitStruct.PLL.PLLRGE = RCC_PLL1VCIRANGE_3;
  RCC_OscInitStruct.PLL.PLLVCOSEL = RCC_PLL1VCOWIDE;
  RCC_OscInitStruct.PLL.PLLFRACN = 0;
  if (HAL_RCC_OscConfig(&RCC_OscInitStruct) != HAL_OK)
  {
    Error_Handler();
  }

  /** Initializes the CPU, AHB and APB buses clocks
  */
  RCC_ClkInitStruct.ClockType = RCC_CLOCKTYPE_HCLK|RCC_CLOCKTYPE_SYSCLK
                              |RCC_CLOCKTYPE_PCLK1|RCC_CLOCKTYPE_PCLK2
                              |RCC_CLOCKTYPE_D3PCLK1|RCC_CLOCKTYPE_D1PCLK1;
  RCC_ClkInitStruct.SYSCLKSource = RCC_SYSCLKSOURCE_PLLCLK;
  RCC_ClkInitStruct.SYSCLKDivider = RCC_SYSCLK_DIV1;
  RCC_ClkInitStruct.AHBCLKDivider = RCC_HCLK_DIV2;
  RCC_ClkInitStruct.APB3CLKDivider = RCC_APB3_DIV2;
  RCC_ClkInitStruct.APB1CLKDivider = RCC_APB1_DIV2;
  RCC_ClkInitStruct.APB2CLKDivider = RCC_APB2_DIV2;
  RCC_ClkInitStruct.APB4CLKDivider = RCC_APB4_DIV2;

  if (HAL_RCC_ClockConfig(&RCC_ClkInitStruct, FLASH_LATENCY_4) != HAL_OK)
  {
    Error_Handler();
  }
}

 /* MPU Configuration */

void MPU_Config(void)
{
  MPU_Region_InitTypeDef MPU_InitStruct = {0};

  /* Disables the MPU */
  HAL_MPU_Disable();

  /** Initializes and configures the Region and the memory to be protected
  */
  MPU_InitStruct.Enable = MPU_REGION_ENABLE;
  MPU_InitStruct.Number = MPU_REGION_NUMBER0;
  MPU_InitStruct.BaseAddress = 0x0;
  MPU_InitStruct.Size = MPU_REGION_SIZE_4GB;
  MPU_InitStruct.SubRegionDisable = 0x87;
  MPU_InitStruct.TypeExtField = MPU_TEX_LEVEL0;
  MPU_InitStruct.AccessPermission = MPU_REGION_FULL_ACCESS;
  MPU_InitStruct.DisableExec = MPU_INSTRUCTION_ACCESS_DISABLE;
  MPU_InitStruct.IsShareable = MPU_ACCESS_SHAREABLE;
  MPU_InitStruct.IsCacheable = MPU_ACCESS_NOT_CACHEABLE;
  MPU_InitStruct.IsBufferable = MPU_ACCESS_NOT_BUFFERABLE;

  HAL_MPU_ConfigRegion(&MPU_InitStruct);
  /* Enables the MPU */
  HAL_MPU_Enable(MPU_PRIVILEGED_DEFAULT);

}

void HAL_TIM_PeriodElapsedCallback(TIM_HandleTypeDef *htim)
{
  if (htim->Instance == TIM1)
  {
    HAL_IncTick();
  }
}

void Error_Handler(void)
{
  __disable_irq();
  while (1)
  {
  }
}

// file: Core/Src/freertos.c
/* USER CODE BEGIN Header */
/**
  ******************************************************************************
  * File Name          : freertos.c
  * Description        : Code for freertos applications
  ******************************************************************************
  * @attention
  *
  * Copyright (c) 2025 STMicroelectronics.
  * All rights reserved.
  *
  * This software is licensed under terms that can be found in the LICENSE file
  * in the root directory of this software component.
  * If no LICENSE file comes with this software, it is provided AS-IS.
  *
  ******************************************************************************
  */

/* USER CODE END Header */

#include "FreeRTOS.h"
#include "task.h"
#include "main.h"
#include "cmsis_os.h"

/* USER CODE BEGIN Includes */
  #include <stdio.h>
	#include <string.h>
	#include <stdlib.h>
	#include "projdefs.h"
	#include "sys.h"
	#include "SDRAM.h"
	#include "dcmi_ov5640.h"
	#include "stm32h7xx_hal.h"
	#include "gimbal.h"
	#include "software_timer.h"
	#include "joystick.h"
	#include "transmit_image.h"
	#include "FOC.h"
	#include "AS5600.h"
/* USER CODE END Includes */

/* USER CODE BEGIN PD */
#define CAMERA_BUF_ADDR	(u32)0xC0000000
#define CAMERA_BUF_SIZE	(128*96*2)/4

#define LED_PORT GPIOA
#define LED_PIN GPIO_PIN_7
/* USER CODE END PD */

/* USER CODE BEGIN Variables */

extern ADC_HandleTypeDef 	hadc1;
extern DMA_HandleTypeDef 	hdma_adc1;
extern UART_HandleTypeDef huart1;
extern TIM_HandleTypeDef 	htim4;
extern TIM_HandleTypeDef 	htim2;
extern TimerHandle_t 			xDebounceTimer;
extern TIM_HandleTypeDef  htim6;
extern TIM_HandleTypeDef  htim7;

extern  PID_TypeDef velPID;
extern  AS5600_HandleTypedef as;
extern  FOC_HandleTypeDef xFOC;

static PID_TypeDef 			xPID_x;
static PID_TypeDef 			xPID_y;
static Gimbal_TypeDef 	xGim;
static Joystick_TypeDef xJoy;
static u16 							pTarget[2];
static u16 							pJoyBuf[2];
static float 						pfRequire[2];
static FlagStatus 			control_mode = RESET;
static QueueHandle_t xServoQueue = NULL;
//static SVPWM_HandleTypeDef foc;

SemaphoreHandle_t xModeChangeSem = NULL;
SemaphoreHandle_t xWaitDMASem = NULL;
SemaphoreHandle_t xMotorSem = NULL;
QueueHandle_t xRxQueue = NULL;

char pUartRx_buf[128];

/* USER CODE END Variables */
osThreadId defaultTaskHandle;

/* USER CODE BEGIN FunctionPrototypes */

void OV5640Task(void *);
void Servotest(void *);
void vModeChangeTask(void *argument);
void test(void *argument);
void ProccessTargetTask(void *argument);
void ProccessRxTask(void *argument);
void ControlTask(void *argument);

HAL_StatusTypeDef SplitKeyVal(char* key, char* val, char* str);
/* USER CODE END FunctionPrototypes */

void StartDefaultTask(void const * argument);

void MX_FREERTOS_Init(void); /* (MISRA C 2004 rule 8.1) */

/* GetIdleTaskMemory prototype (linked to static allocation support) */
void vApplicationGetIdleTaskMemory( StaticTask_t **ppxIdleTaskTCBBuffer, StackType_t **ppxIdleTaskStackBuffer, uint32_t *pulIdleTaskStackSize );

/* GetTimerTaskMemory prototype (linked to static allocation support) */
void vApplicationGetTimerTaskMemory( StaticTask_t **ppxTimerTaskTCBBuffer, StackType_t **ppxTimerTaskStackBuffer, uint32_t *pulTimerTaskStackSize );

/* USER CODE BEGIN GET_IDLE_TASK_MEMORY */
static StaticTask_t xIdleTaskTCBBuffer;
static StackType_t xIdleStack[configMINIMAL_STACK_SIZE];

void vApplicationGetIdleTaskMemory( StaticTask_t **ppxIdleTaskTCBBuffer, StackType_t **ppxIdleTaskStackBuffer, uint32_t *pulIdleTaskStackSize )
{
  *ppxIdleTaskTCBBuffer = &xIdleTaskTCBBuffer;
  *ppxIdleTaskStackBuffer = &xIdleStack[0];
  *pulIdleTaskStackSize = configMINIMAL_STACK_SIZE;
  /* place for user code */
}
/* USER CODE END GET_IDLE_TASK_MEMORY */

/* USER CODE BEGIN GET_TIMER_TASK_MEMORY */
static StaticTask_t xTimerTaskTCBBuffer;
static StackType_t xTimerStack[configTIMER_TASK_STACK_DEPTH];

void vApplicationGetTimerTaskMemory( StaticTask_t **ppxTimerTaskTCBBuffer, StackType_t **ppxTimerTaskStackBuffer, uint32_t *pulTimerTaskStackSize )
{
  *ppxTimerTaskTCBBuffer = &xTimerTaskTCBBuffer;
  *ppxTimerTaskStackBuffer = &xTimerStack[0];
  *pulTimerTaskStackSize = configTIMER_TASK_STACK_DEPTH;
  /* place for user code */
}
/* USER CODE END GET_TIMER_TASK_MEMORY */

void MX_FREERTOS_Init(void) {
  /* USER CODE BEGIN Init */
	//Calibration ADC
	HAL_ADCEx_Calibration_Start(&hadc1, ADC_CALIB_OFFSET, ADC_SINGLE_ENDED);
	Gimbal_Init(&xPID_x, &xPID_y, &xJoy, &xGim);

	HAL_TIM_PWM_Start(&htim4,TIM_CHANNEL_1);
	HAL_TIM_PWM_Start(&htim4,TIM_CHANNEL_2);
	HAL_TIM_Base_Start_IT(&htim6);
	HAL_TIM_Base_Start_IT(&htim7);

	HAL_UARTEx_ReceiveToIdle_DMA(&huart1, (u8*)pUartRx_buf, sizeof(pUartRx_buf));
	__HAL_DMA_DISABLE_IT(huart1.hdmarx, DMA_IT_HT);

	SVPWM_Init();
  /* USER CODE END Init */

  /* USER CODE BEGIN RTOS_SEMAPHORES */
  /* add semaphores, ... */
	xModeChangeSem = xSemaphoreCreateBinary();
	xWaitDMASem = xSemaphoreCreateBinary();
	xMotorSem = xSemaphoreCreateBinary();

	xSemaphoreGive(xModeChangeSem);
  /* USER CODE END RTOS_SEMAPHORES */

  /* USER CODE BEGIN RTOS_TIMERS */
  /* start timers, add new ones, ... */
	xDebounceTimer = xTimerCreate("DebounceTimer", pdMS_TO_TICKS(20), pdFALSE, (void*)0, vDebounceTimerCallback);
  /* USER CODE END RTOS_TIMERS */

  /* USER CODE BEGIN RTOS_QUEUES */
  /* add queues, ... */
	xServoQueue = xQueueCreate(1, sizeof(ServoInc_TypeDef));
	xRxQueue = xQueueCreate(5, sizeof(pUartRx_buf));
  /* USER CODE END RTOS_QUEUES */

  /* Create the thread(s) */
  /* definition and creation of defaultTask */
  osThreadDef(defaultTask, StartDefaultTask, osPriorityNormal, 0, 128);
  defaultTaskHandle = osThreadCreate(osThread(defaultTask), NULL);

  /* USER CODE BEGIN RTOS_THREADS */
  /* add threads, ... */

  xTaskCreate(test, "test", 256, NULL, osPriorityAboveNormal, NULL);
  //xTaskCreate(OV5640Task, "OV5640Task", 128, NULL, osPriorityAboveNormal, NULL);
  //xTaskCreate(vModeChangeTask, "vModeChangeTask", 128, NULL, osPriorityAboveNormal, NULL);
	//xTaskCreate(ProccessTargetTask, "ProccessTargetTask", 128, NULL, osPriorityAboveNormal, NULL);
	xTaskCreate(ProccessRxTask, "ProccessRxTask", 256, NULL, osPriorityAboveNormal, NULL);
	//xTaskCreate(ControlTask, "ControlTask", 128, NULL, osPriorityAboveNormal, NULL);

  /* USER CODE END RTOS_THREADS */

}

void StartDefaultTask(void const * argument)
{
  for(;;)
  {
		osDelay(1);
  }
}

/* USER CODE BEGIN Application */

float velocity = 10;
float angle = 0;
extern FOC_HandleTypeDef xSPWMFOC;
void test(void *argument)
{
	SVPWM_Init();
	float angle = 0;
	while(1)
	{
		xSemaphoreTake(xMotorSem, portMAX_DELAY);
		SVPWM_CalcForTargetVelocity(&xFOC, velocity);
		//SVPWM_CalcForTargetAngle(&foc, angle);
		//SPWM_CalcForTargetVelocity(&xSPWMFOC, velocity);
		//SPWM_CalcForTargetAngle(&xSPWMFOC, angle);
	}
}

void vModeChangeTask(void *argument)
{
	while(1)
	{
			xSemaphoreTake(xModeChangeSem, portMAX_DELAY);

			control_mode = control_mode ? RESET : SET;
			if(control_mode)
			{
				//Turn on LED
				HAL_GPIO_WritePin(LED_PORT, LED_PIN, GPIO_PIN_SET);
				HAL_ADC_Start_DMA(&hadc1, (uint32_t*)pJoyBuf, 2);
			}
			else
			{
				//Turn off LED
				HAL_GPIO_WritePin(LED_PORT, LED_PIN, GPIO_PIN_RESET);
				// stop ADC2DMA
//				HAL_ADC_Stop_DMA(&hadc1);
//
//				// stop ADC Collect
//				HAL_ADC_Stop(&hadc1);
//
//				// clear DMA flag
//				__HAL_DMA_CLEAR_FLAG(&hdma_adc1, __HAL_DMA_GET_TC_FLAG_INDEX(&hdma_adc1));
			}

		printf("JOYSTICKBTN Trigger:%s\r\n", control_mode ? "Manual" : "Auto");

	}
}

void ProccessTargetTask(void *argument)
{
	ServoInc_TypeDef xServoInc;
	while(1)
	{
		if(control_mode)
		{
			//Mannul
			Process_Joystick(&xJoy, pJoyBuf, &xServoInc);
		}else
		{
			//Auto-----
			Process_AIResult(&xPID_x, &xPID_y, pfRequire, pTarget, &xServoInc);
		}
		vTaskDelay(pdMS_TO_TICKS(12));
		xQueueOverwrite(xServoQueue, &xServoInc);

	}
}

void ProccessRxTask(void *argument)
{
	char pData[128];
	char key[8];
	char val[5];
	float value;
	while(1)
	{
		xQueueReceive(xRxQueue, pData, portMAX_DELAY);

		if(SplitKeyVal(key, val, pData) == HAL_ERROR) continue;
		value = atof(val);
		if(strcmp(key, "uq") == 0)
		{
			xFOC.Uq = value;
		}else if(strcmp(key, "vel") == 0)
		{
			velocity = value;
		}else if(strcmp(key, "vp") == 0)
		{
			velPID.Kp = value;
		}else if(strcmp(key, "vi") == 0)
		{
			velPID.Ki = value;
		}else if(strcmp(key, "vd") == 0)
		{
			velPID.Kd = value;
		}else if(strcmp(key, "angle") == 0)
		{
			angle = value;
		}

	}
}

void ControlTask(void *argument)
{
	ServoInc_TypeDef xServoInc;
	while(1)
	{
		xQueueReceive(xServoQueue, &xServoInc, portMAX_DELAY);
		Control_Loop(&xGim, xServoInc);
	}
}

void OV5640Task(void *argument)
{
	//OV5640_DMA_Transmit_Continuous(Camera_Buffer_addr, Camera_Buffer_Size);
	OV5640_DMA_Transmit_Snapshot(CAMERA_BUF_ADDR, CAMERA_BUF_SIZE);
	while(1)
	{
		vTaskDelay(2000);
		printf("task..\r\n");
		if ( OV5640_FrameState == 1 )
		{
  			OV5640_FrameState = 0;
//				printf("array:");
//				for(int i = 0; i < 100;i++)
//					printf("%x ",array[i]);
		}
	}
}

HAL_StatusTypeDef SplitKeyVal(char* key, char* val, char* str)
{
	char *key_ptr = NULL,*val_ptr = NULL;

	key_ptr = strtok(str, "=");
	if(key_ptr == NULL || strlen(key_ptr) == 0) return HAL_ERROR;

	val_ptr = strtok(NULL, "=");
	if(val_ptr == NULL || strlen(val_ptr) == 0) return HAL_ERROR;

	if(strlen(key_ptr) > 5 || strlen(val_ptr) > 5) return HAL_ERROR;

	strcpy(key, key_ptr);
	strcpy(val, val_ptr);
	return HAL_OK;
}

/* USER CODE END Application */
